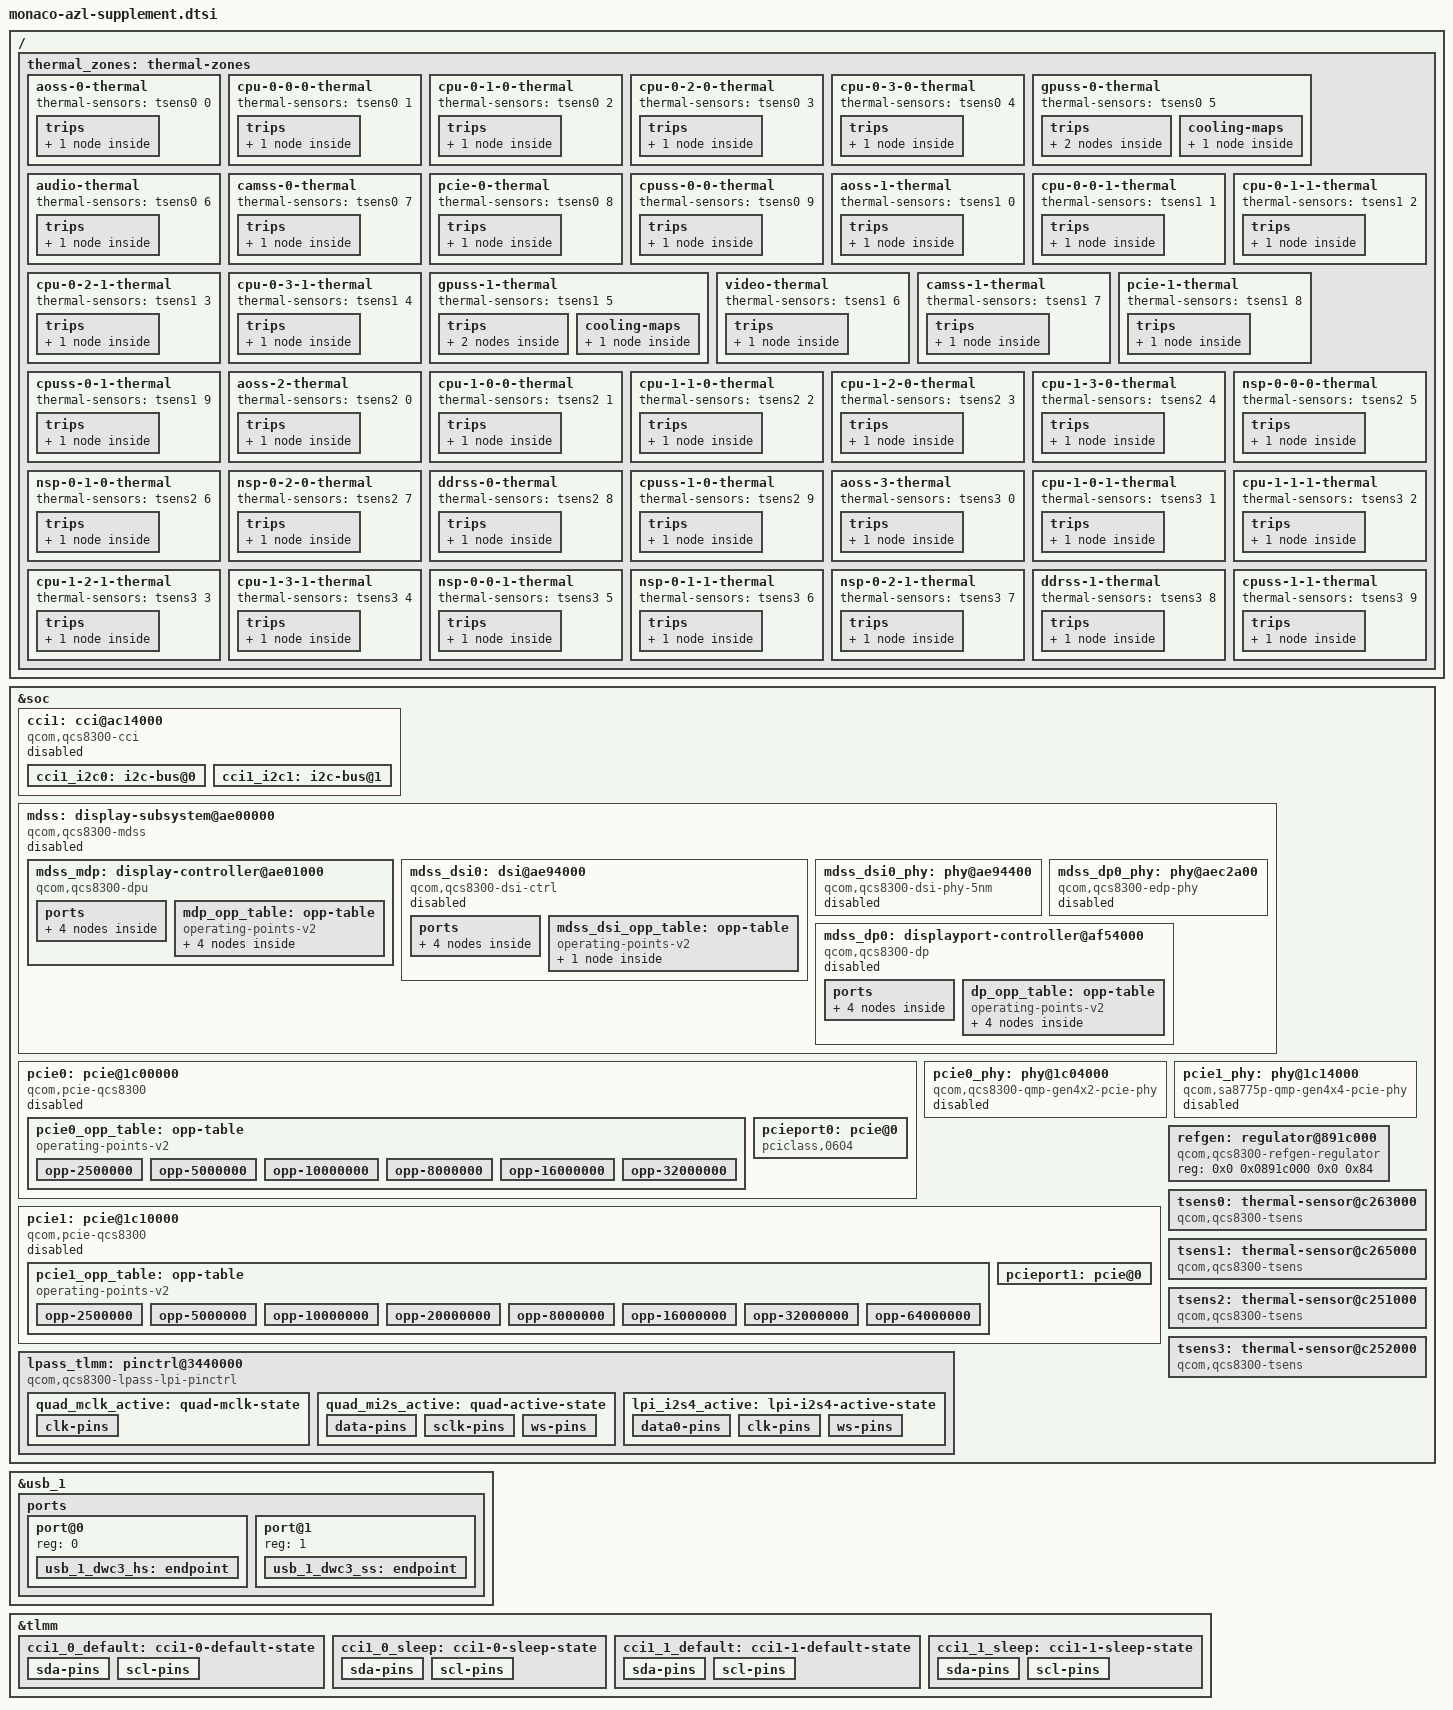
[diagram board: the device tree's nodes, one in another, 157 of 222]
// SPDX-License-Identifier: BSD-3-Clause
/*
 * Supplement for the Azure Linux 6.18 qcs8300.dtsi: the Monaco node
 * subtrees the Arduino Monza board files reference that the Azure
 * tree's SoC file does not carry. Extracted from upstream
 * monaco.dtsi (torvalds/linux) Nov 9, 2026: display (mdss with its
 * dp/dsi children), PCIe controllers and PHYs, camera CCI, refgen,
 * the thermal sensors, and the Type-C graph endpoints. The thermal
 * bindings include comes with it; upstream monaco.dtsi provides
 * THERMAL_NO_LIMIT transitively and the Azure file does not.
 */

#include <dt-bindings/clock/qcom,dsi-phy-28nm.h>
#include <dt-bindings/thermal/thermal.h>

&soc {
			cci1: cci@ac14000 {

				compatible = "qcom,qcs8300-cci", "qcom,msm8996-cci";

				reg = <0x0 0x0ac14000 0x0 0x1000>;



				interrupts = <GIC_SPI 271 IRQ_TYPE_EDGE_RISING>;



				clocks = <&camcc CAM_CC_CPAS_AHB_CLK>,

					 <&camcc CAM_CC_CCI_1_CLK>;

				clock-names = "ahb",

					      "cci";



				power-domains = <&camcc CAM_CC_TITAN_TOP_GDSC>;



				pinctrl-0 = <&cci1_0_default &cci1_1_default>;

				pinctrl-1 = <&cci1_0_sleep &cci1_1_sleep>;

				pinctrl-names = "default", "sleep";



				#address-cells = <1>;

				#size-cells = <0>;



				status = "disabled";



				cci1_i2c0: i2c-bus@0 {

					reg = <0>;

					clock-frequency = <400000>;

					#address-cells = <1>;

					#size-cells = <0>;

				};



				cci1_i2c1: i2c-bus@1 {

					reg = <1>;

					clock-frequency = <400000>;

					#address-cells = <1>;

					#size-cells = <0>;

				};

			};



			mdss: display-subsystem@ae00000 {

				compatible = "qcom,qcs8300-mdss";

				reg = <0x0 0x0ae00000 0x0 0x1000>;

				reg-names = "mdss";



				interrupts = <GIC_SPI 92 IRQ_TYPE_LEVEL_HIGH>;



				clocks = <&dispcc MDSS_DISP_CC_MDSS_AHB_CLK>,

					 <&gcc GCC_DISP_HF_AXI_CLK>,

					 <&dispcc MDSS_DISP_CC_MDSS_MDP_CLK>;



				resets = <&dispcc MDSS_DISP_CC_MDSS_CORE_BCR>;



				interconnects = <&mmss_noc MASTER_MDP0 QCOM_ICC_TAG_ALWAYS

						 &mc_virt SLAVE_EBI1 QCOM_ICC_TAG_ALWAYS>,

						<&mmss_noc MASTER_MDP1 QCOM_ICC_TAG_ALWAYS

						 &mc_virt SLAVE_EBI1 QCOM_ICC_TAG_ALWAYS>,

						<&gem_noc MASTER_APPSS_PROC QCOM_ICC_TAG_ACTIVE_ONLY

						 &config_noc SLAVE_DISPLAY_CFG QCOM_ICC_TAG_ACTIVE_ONLY>;

				interconnect-names = "mdp0-mem",

						     "mdp1-mem",

						     "cpu-cfg";



				power-domains = <&dispcc MDSS_DISP_CC_MDSS_CORE_GDSC>;



				iommus = <&apps_smmu 0x1000 0x402>;



				interrupt-controller;

				#interrupt-cells = <1>;



				#address-cells = <2>;

				#size-cells = <2>;

				ranges;



				status = "disabled";



				mdss_mdp: display-controller@ae01000 {

					compatible = "qcom,qcs8300-dpu", "qcom,sa8775p-dpu";

					reg = <0x0 0x0ae01000 0x0 0x8f000>,

					      <0x0 0x0aeb0000 0x0 0x2008>;

					reg-names = "mdp", "vbif";



					interrupts-extended = <&mdss 0>;



					clocks = <&gcc GCC_DISP_HF_AXI_CLK>,

						 <&dispcc MDSS_DISP_CC_MDSS_AHB_CLK>,

						 <&dispcc MDSS_DISP_CC_MDSS_MDP_LUT_CLK>,

						 <&dispcc MDSS_DISP_CC_MDSS_MDP_CLK>,

						 <&dispcc MDSS_DISP_CC_MDSS_VSYNC_CLK>;

					clock-names = "nrt_bus",

						      "iface",

						      "lut",

						      "core",

						      "vsync";



					assigned-clocks = <&dispcc MDSS_DISP_CC_MDSS_VSYNC_CLK>;

					assigned-clock-rates = <19200000>;



					operating-points-v2 = <&mdp_opp_table>;

					power-domains = <&rpmhpd RPMHPD_MMCX>;



					ports {

						#address-cells = <1>;

						#size-cells = <0>;



						port@0 {

							reg = <0>;



							dpu_intf0_out: endpoint {



								remote-endpoint = <&mdss_dp0_in>;

							};

						};



						port@1 {

							reg = <1>;



							dpu_intf1_out: endpoint {



								remote-endpoint = <&mdss_dsi0_in>;

							};

						};

					};



					mdp_opp_table: opp-table {

						compatible = "operating-points-v2";



						opp-375000000 {

							opp-hz = /bits/ 64 <375000000>;

							required-opps = <&rpmhpd_opp_svs_l1>;

						};



						opp-500000000 {

							opp-hz = /bits/ 64 <500000000>;

							required-opps = <&rpmhpd_opp_nom>;

						};



						opp-575000000 {

							opp-hz = /bits/ 64 <575000000>;

							required-opps = <&rpmhpd_opp_turbo>;

						};



						opp-650000000 {

							opp-hz = /bits/ 64 <650000000>;

							required-opps = <&rpmhpd_opp_turbo_l1>;

						};

					};

				};



				mdss_dsi0: dsi@ae94000 {

					compatible = "qcom,qcs8300-dsi-ctrl",

						     "qcom,sa8775p-dsi-ctrl",

						     "qcom,mdss-dsi-ctrl";

					reg = <0x0 0x0ae94000 0x0 0x400>;

					reg-names = "dsi_ctrl";



					interrupt-parent = <&mdss>;

					interrupts = <4>;



					clocks = <&dispcc MDSS_DISP_CC_MDSS_BYTE0_CLK>,

						 <&dispcc MDSS_DISP_CC_MDSS_BYTE0_INTF_CLK>,

						 <&dispcc MDSS_DISP_CC_MDSS_PCLK0_CLK>,

						 <&dispcc MDSS_DISP_CC_MDSS_ESC0_CLK>,

						 <&dispcc MDSS_DISP_CC_MDSS_AHB_CLK>,

						 <&gcc GCC_DISP_HF_AXI_CLK>;

					clock-names = "byte",

						      "byte_intf",

						      "pixel",

						      "core",

						      "iface",

						      "bus";



					assigned-clocks = <&dispcc MDSS_DISP_CC_MDSS_BYTE0_CLK_SRC>,

							  <&dispcc MDSS_DISP_CC_MDSS_PCLK0_CLK_SRC>;

					assigned-clock-parents = <&mdss_dsi0_phy DSI_BYTE_PLL_CLK>,

								 <&mdss_dsi0_phy DSI_PIXEL_PLL_CLK>;



					phys = <&mdss_dsi0_phy>;



					operating-points-v2 = <&mdss_dsi_opp_table>;

					power-domains = <&rpmhpd RPMHPD_MMCX>;



					refgen-supply = <&refgen>;



					#address-cells = <1>;

					#size-cells = <0>;



					status = "disabled";



					ports {

						#address-cells = <1>;

						#size-cells = <0>;



						port@0 {

							reg = <0>;



							mdss_dsi0_in: endpoint {



								remote-endpoint = <&dpu_intf1_out>;

							};

						};



						port@1 {

							reg = <1>;



							mdss_dsi0_out: endpoint {

							};

						};

					};



					mdss_dsi_opp_table: opp-table {

						compatible = "operating-points-v2";



						opp-358000000 {

							opp-hz = /bits/ 64 <358000000>;

							required-opps = <&rpmhpd_opp_svs_l1>;

						};

					};

				};



				mdss_dsi0_phy: phy@ae94400 {

					compatible = "qcom,qcs8300-dsi-phy-5nm",

						     "qcom,sa8775p-dsi-phy-5nm";

					reg = <0x0 0x0ae94400 0x0 0x200>,

					      <0x0 0x0ae94600 0x0 0x280>,

					      <0x0 0x0ae94900 0x0 0x280>;

					reg-names = "dsi_phy",

						    "dsi_phy_lane",

						    "dsi_pll";



					#clock-cells = <1>;

					#phy-cells = <0>;



					clocks = <&dispcc MDSS_DISP_CC_MDSS_AHB_CLK>,

						 <&rpmhcc RPMH_CXO_CLK>;

					clock-names = "iface",

						      "ref";



					status = "disabled";

				};



				mdss_dp0_phy: phy@aec2a00 {

					compatible = "qcom,qcs8300-edp-phy", "qcom,sa8775p-edp-phy";



					reg = <0x0 0x0aec2a00 0x0 0x19c>,

					      <0x0 0x0aec2200 0x0 0xec>,

					      <0x0 0x0aec2600 0x0 0xec>,

					      <0x0 0x0aec2000 0x0 0x1c8>;



					clocks = <&dispcc MDSS_DISP_CC_MDSS_DPTX0_AUX_CLK>,

						 <&dispcc MDSS_DISP_CC_MDSS_AHB_CLK>;

					clock-names = "aux",

						      "cfg_ahb";



					power-domains = <&rpmhpd RPMHPD_MX>;



					#clock-cells = <1>;

					#phy-cells = <0>;



					status = "disabled";

				};



				mdss_dp0: displayport-controller@af54000 {

					compatible = "qcom,qcs8300-dp", "qcom,sa8775p-dp";



					reg = <0x0 0x0af54000 0x0 0x200>,

					      <0x0 0x0af54200 0x0 0x200>,

					      <0x0 0x0af55000 0x0 0xc00>,

					      <0x0 0x0af56000 0x0 0x09c>,

					      <0x0 0x0af57000 0x0 0x09c>,

					      <0x0 0x0af58000 0x0 0x09c>,

					      <0x0 0x0af59000 0x0 0x09c>,

					      <0x0 0x0af5a000 0x0 0x23c>,

					      <0x0 0x0af5b000 0x0 0x23c>;



					interrupts-extended = <&mdss 12>;



					clocks = <&dispcc MDSS_DISP_CC_MDSS_AHB_CLK>,

						 <&dispcc MDSS_DISP_CC_MDSS_DPTX0_AUX_CLK>,

						 <&dispcc MDSS_DISP_CC_MDSS_DPTX0_LINK_CLK>,

						 <&dispcc MDSS_DISP_CC_MDSS_DPTX0_LINK_INTF_CLK>,

						 <&dispcc MDSS_DISP_CC_MDSS_DPTX0_PIXEL0_CLK>,

						 <&dispcc MDSS_DISP_CC_MDSS_DPTX0_PIXEL1_CLK>,

						 <&dispcc MDSS_DISP_CC_MDSS_DPTX0_PIXEL2_CLK>,

						 <&dispcc MDSS_DISP_CC_MDSS_DPTX0_PIXEL3_CLK>;

					clock-names = "core_iface",

						      "core_aux",

						      "ctrl_link",

						      "ctrl_link_iface",

						      "stream_pixel",

						      "stream_1_pixel",

						      "stream_2_pixel",

						      "stream_3_pixel";

					assigned-clocks = <&dispcc MDSS_DISP_CC_MDSS_DPTX0_LINK_CLK_SRC>,

							  <&dispcc MDSS_DISP_CC_MDSS_DPTX0_PIXEL0_CLK_SRC>,

							  <&dispcc MDSS_DISP_CC_MDSS_DPTX0_PIXEL1_CLK_SRC>,

							  <&dispcc MDSS_DISP_CC_MDSS_DPTX0_PIXEL2_CLK_SRC>,

							  <&dispcc MDSS_DISP_CC_MDSS_DPTX0_PIXEL3_CLK_SRC>;

					assigned-clock-parents = <&mdss_dp0_phy 0>,

								 <&mdss_dp0_phy 1>,

								 <&mdss_dp0_phy 1>,

								 <&mdss_dp0_phy 1>,

								 <&mdss_dp0_phy 1>;

					phys = <&mdss_dp0_phy>;

					phy-names = "dp";



					operating-points-v2 = <&dp_opp_table>;

					power-domains = <&rpmhpd RPMHPD_MMCX>;



					#sound-dai-cells = <0>;



					status = "disabled";



					ports {

						#address-cells = <1>;

						#size-cells = <0>;



						port@0 {

							reg = <0>;



							mdss_dp0_in: endpoint {

								remote-endpoint = <&dpu_intf0_out>;

							};

						};



						port@1 {

							reg = <1>;



							mdss_dp0_out: endpoint { };

						};

					};



					dp_opp_table: opp-table {

						compatible = "operating-points-v2";



						opp-162000000 {

							opp-hz = /bits/ 64 <162000000>;

							required-opps = <&rpmhpd_opp_low_svs>;

						};



						opp-270000000 {

							opp-hz = /bits/ 64 <270000000>;

							required-opps = <&rpmhpd_opp_svs>;

						};



						opp-540000000 {

							opp-hz = /bits/ 64 <540000000>;

							required-opps = <&rpmhpd_opp_svs_l1>;

						};



						opp-810000000 {

							opp-hz = /bits/ 64 <810000000>;

							required-opps = <&rpmhpd_opp_nom>;

						};

					};

				};

			};



			pcie0: pcie@1c00000 {

				device_type = "pci";

				compatible = "qcom,pcie-qcs8300", "qcom,pcie-sa8775p";

				reg = <0x0 0x01c00000 0x0 0x3000>,

				      <0x0 0x40000000 0x0 0xf20>,

				      <0x0 0x40000f20 0x0 0xa8>,

				      <0x0 0x40001000 0x0 0x4000>,

				      <0x0 0x40100000 0x0 0x100000>,

				      <0x0 0x01c03000 0x0 0x1000>;

				reg-names = "parf",

					    "dbi",

					    "elbi",

					    "atu",

					    "config",

					    "mhi";

				#address-cells = <3>;

				#size-cells = <2>;

				ranges = <0x01000000 0x0 0x00000000 0x0 0x40200000 0x0 0x100000>,

					 <0x02000000 0x0 0x40300000 0x0 0x40300000 0x0 0x1fd00000>;

				bus-range = <0x00 0xff>;



				dma-coherent;



				linux,pci-domain = <0>;

				num-lanes = <2>;



				interrupts = <GIC_SPI 307 IRQ_TYPE_LEVEL_HIGH>,

					     <GIC_SPI 308 IRQ_TYPE_LEVEL_HIGH>,

					     <GIC_SPI 309 IRQ_TYPE_LEVEL_HIGH>,

					     <GIC_SPI 312 IRQ_TYPE_LEVEL_HIGH>,

					     <GIC_SPI 313 IRQ_TYPE_LEVEL_HIGH>,

					     <GIC_SPI 314 IRQ_TYPE_LEVEL_HIGH>,

					     <GIC_SPI 374 IRQ_TYPE_LEVEL_HIGH>,

					     <GIC_SPI 375 IRQ_TYPE_LEVEL_HIGH>,

					     <GIC_SPI 306 IRQ_TYPE_LEVEL_HIGH>;

				interrupt-names = "msi0",

						  "msi1",

						  "msi2",

						  "msi3",

						  "msi4",

						  "msi5",

						  "msi6",

						  "msi7",

						  "global";



				#interrupt-cells = <1>;

				interrupt-map-mask = <0 0 0 0x7>;

				interrupt-map = <0 0 0 1 &intc GIC_SPI 434 IRQ_TYPE_LEVEL_HIGH>,

						<0 0 0 2 &intc GIC_SPI 435 IRQ_TYPE_LEVEL_HIGH>,

						<0 0 0 3 &intc GIC_SPI 438 IRQ_TYPE_LEVEL_HIGH>,

						<0 0 0 4 &intc GIC_SPI 439 IRQ_TYPE_LEVEL_HIGH>;



				clocks = <&gcc GCC_PCIE_0_AUX_CLK>,

					 <&gcc GCC_PCIE_0_CFG_AHB_CLK>,

					 <&gcc GCC_PCIE_0_MSTR_AXI_CLK>,

					 <&gcc GCC_PCIE_0_SLV_AXI_CLK>,

					 <&gcc GCC_PCIE_0_SLV_Q2A_AXI_CLK>;

				clock-names = "aux",

					      "cfg",

					      "bus_master",

					      "bus_slave",

					      "slave_q2a";



				assigned-clocks = <&gcc GCC_PCIE_0_AUX_CLK>;

				assigned-clock-rates = <19200000>;



				interconnects = <&pcie_anoc MASTER_PCIE_0 QCOM_ICC_TAG_ALWAYS

						 &mc_virt SLAVE_EBI1 QCOM_ICC_TAG_ALWAYS>,

						<&gem_noc MASTER_APPSS_PROC QCOM_ICC_TAG_ACTIVE_ONLY

						 &config_noc SLAVE_PCIE_0 QCOM_ICC_TAG_ACTIVE_ONLY>;

				interconnect-names = "pcie-mem",

						     "cpu-pcie";



				iommu-map = <0x0 &pcie_smmu 0x0000 0x0 0x1>,

					    <0x100 &pcie_smmu 0x0001 0x0 0x1>;



				resets = <&gcc GCC_PCIE_0_BCR>,

					 <&gcc GCC_PCIE_0_LINK_DOWN_BCR>;

				reset-names = "pci",

					      "link_down";



				power-domains = <&gcc GCC_PCIE_0_GDSC>;



				eq-presets-8gts = /bits/ 16 <0x5555 0x5555>;

				eq-presets-16gts = /bits/ 8 <0x55 0x55>;



				operating-points-v2 = <&pcie0_opp_table>;



				status = "disabled";



				pcie0_opp_table: opp-table {

					compatible = "operating-points-v2";



					/* GEN 1 x1 */

					opp-2500000 {

						opp-hz = /bits/ 64 <2500000>;

						required-opps = <&rpmhpd_opp_svs_l1>;

						opp-peak-kBps = <250000 1>;

					};



					/* GEN 1 x2 and GEN 2 x1 */

					opp-5000000 {

						opp-hz = /bits/ 64 <5000000>;

						required-opps = <&rpmhpd_opp_svs_l1>;

						opp-peak-kBps = <500000 1>;

					};



					/* GEN 2 x2 */

					opp-10000000 {

						opp-hz = /bits/ 64 <10000000>;

						required-opps = <&rpmhpd_opp_svs_l1>;

						opp-peak-kBps = <1000000 1>;

					};



					/* GEN 3 x1 */

					opp-8000000 {

						opp-hz = /bits/ 64 <8000000>;

						required-opps = <&rpmhpd_opp_svs_l1>;

						opp-peak-kBps = <984500 1>;

					};



					/* GEN 3 x2 and GEN 4 x1 */

					opp-16000000 {

						opp-hz = /bits/ 64 <16000000>;

						required-opps = <&rpmhpd_opp_nom>;

						opp-peak-kBps = <1969000 1>;

					};



					/* GEN 4 x2 */

					opp-32000000 {

						opp-hz = /bits/ 64 <32000000>;

						required-opps = <&rpmhpd_opp_nom>;

						opp-peak-kBps = <3938000 1>;

					};

				};



				pcieport0: pcie@0 {

					compatible = "pciclass,0604";

					device_type = "pci";

					reg = <0x0 0x0 0x0 0x0 0x0>;

					bus-range = <0x01 0xff>;



					#address-cells = <3>;

					#size-cells = <2>;

					ranges;

					phys = <&pcie0_phy>;

				};

			};



			pcie0_phy: phy@1c04000 {

				compatible = "qcom,qcs8300-qmp-gen4x2-pcie-phy";

				reg = <0x0 0x01c04000 0x0 0x2000>;



				clocks = <&gcc GCC_PCIE_0_PHY_AUX_CLK>,

					 <&gcc GCC_PCIE_0_CFG_AHB_CLK>,

					 <&gcc GCC_PCIE_CLKREF_EN>,

					 <&gcc GCC_PCIE_0_PHY_RCHNG_CLK>,

					 <&gcc GCC_PCIE_0_PIPE_CLK>,

					 <&gcc GCC_PCIE_0_PIPEDIV2_CLK>;

				clock-names = "aux",

					      "cfg_ahb",

					      "ref",

					      "rchng",

					      "pipe",

					      "pipediv2";



				resets = <&gcc GCC_PCIE_0_PHY_BCR>;

				reset-names = "phy";



				assigned-clocks = <&gcc GCC_PCIE_0_PHY_RCHNG_CLK>;

				assigned-clock-rates = <100000000>;



				#clock-cells = <0>;

				clock-output-names = "pcie_0_pipe_clk";



				#phy-cells = <0>;



				status = "disabled";

			};



			pcie1: pcie@1c10000 {

				device_type = "pci";

				compatible = "qcom,pcie-qcs8300", "qcom,pcie-sa8775p";

				reg = <0x0 0x01c10000 0x0 0x3000>,

				      <0x0 0x60000000 0x0 0xf20>,

				      <0x0 0x60000f20 0x0 0xa8>,

				      <0x0 0x60001000 0x0 0x4000>,

				      <0x0 0x60100000 0x0 0x100000>,

				      <0x0 0x01c13000 0x0 0x1000>;

				reg-names = "parf",

					    "dbi",

					    "elbi",

					    "atu",

					    "config",

					    "mhi";

				#address-cells = <3>;

				#size-cells = <2>;

				ranges = <0x01000000 0x0 0x00000000 0x0 0x60200000 0x0 0x100000>,

					 <0x02000000 0x0 0x60300000 0x0 0x60300000 0x0 0x1fd00000>;

				bus-range = <0x00 0xff>;



				dma-coherent;



				linux,pci-domain = <1>;

				num-lanes = <4>;



				interrupts = <GIC_SPI 519 IRQ_TYPE_LEVEL_HIGH>,

					     <GIC_SPI 140 IRQ_TYPE_LEVEL_HIGH>,

					     <GIC_SPI 141 IRQ_TYPE_LEVEL_HIGH>,

					     <GIC_SPI 142 IRQ_TYPE_LEVEL_HIGH>,

					     <GIC_SPI 143 IRQ_TYPE_LEVEL_HIGH>,

					     <GIC_SPI 144 IRQ_TYPE_LEVEL_HIGH>,

					     <GIC_SPI 145 IRQ_TYPE_LEVEL_HIGH>,

					     <GIC_SPI 146 IRQ_TYPE_LEVEL_HIGH>,

					     <GIC_SPI 518 IRQ_TYPE_LEVEL_HIGH>;

				interrupt-names = "msi0",

						  "msi1",

						  "msi2",

						  "msi3",

						  "msi4",

						  "msi5",

						  "msi6",

						  "msi7",

						  "global";

				#interrupt-cells = <1>;

				interrupt-map-mask = <0 0 0 0x7>;

				interrupt-map = <0 0 0 1 &intc GIC_SPI 148 IRQ_TYPE_LEVEL_HIGH>,

						<0 0 0 2 &intc GIC_SPI 149 IRQ_TYPE_LEVEL_HIGH>,

						<0 0 0 3 &intc GIC_SPI 150 IRQ_TYPE_LEVEL_HIGH>,

						<0 0 0 4 &intc GIC_SPI 151 IRQ_TYPE_LEVEL_HIGH>;



				clocks = <&gcc GCC_PCIE_1_AUX_CLK>,

					 <&gcc GCC_PCIE_1_CFG_AHB_CLK>,

					 <&gcc GCC_PCIE_1_MSTR_AXI_CLK>,

					 <&gcc GCC_PCIE_1_SLV_AXI_CLK>,

					 <&gcc GCC_PCIE_1_SLV_Q2A_AXI_CLK>;

				clock-names = "aux",

					      "cfg",

					      "bus_master",

					      "bus_slave",

					      "slave_q2a";



				assigned-clocks = <&gcc GCC_PCIE_1_AUX_CLK>;

				assigned-clock-rates = <19200000>;



				interconnects = <&pcie_anoc MASTER_PCIE_1 QCOM_ICC_TAG_ALWAYS

						 &mc_virt SLAVE_EBI1 QCOM_ICC_TAG_ALWAYS>,

						<&gem_noc MASTER_APPSS_PROC QCOM_ICC_TAG_ACTIVE_ONLY

						 &config_noc SLAVE_PCIE_1 QCOM_ICC_TAG_ACTIVE_ONLY>;

				interconnect-names = "pcie-mem", "cpu-pcie";



				iommu-map = <0x0 &pcie_smmu 0x0080 0x0 0x1>,

					    <0x100 &pcie_smmu 0x0081 0x0 0x1>;



				resets = <&gcc GCC_PCIE_1_BCR>,

					 <&gcc GCC_PCIE_1_LINK_DOWN_BCR>;

				reset-names = "pci",

					      "link_down";



				power-domains = <&gcc GCC_PCIE_1_GDSC>;



				eq-presets-8gts = /bits/ 16 <0x5555 0x5555 0x5555 0x5555>;

				eq-presets-16gts = /bits/ 8 <0x55 0x55 0x55 0x55>;



				operating-points-v2 = <&pcie1_opp_table>;



				status = "disabled";



				pcie1_opp_table: opp-table {

					compatible = "operating-points-v2";



					/* GEN 1 x1 */

					opp-2500000 {

						opp-hz = /bits/ 64 <2500000>;

						required-opps = <&rpmhpd_opp_svs_l1>;

						opp-peak-kBps = <250000 1>;

					};



					/* GEN 1 x2 and GEN 2 x1 */

					opp-5000000 {

						opp-hz = /bits/ 64 <5000000>;

						required-opps = <&rpmhpd_opp_svs_l1>;

						opp-peak-kBps = <500000 1>;

					};



					/* GEN 1 x4 and GEN 2 x2 */

					opp-10000000 {

						opp-hz = /bits/ 64 <10000000>;

						required-opps = <&rpmhpd_opp_svs_l1>;

						opp-peak-kBps = <1000000 1>;

					};



					/* GEN 2 x4 */

					opp-20000000 {

						opp-hz = /bits/ 64 <20000000>;

						required-opps = <&rpmhpd_opp_low_svs>;

						opp-peak-kBps = <2000000 1>;

					};



					/* GEN 3 x1 */

					opp-8000000 {

						opp-hz = /bits/ 64 <8000000>;

						required-opps = <&rpmhpd_opp_svs_l1>;

						opp-peak-kBps = <984500 1>;

					};



					/* GEN 3 x2 and GEN 4 x1 */

					opp-16000000 {

						opp-hz = /bits/ 64 <16000000>;

						required-opps = <&rpmhpd_opp_nom>;

						opp-peak-kBps = <1969000 1>;

					};



					/* GEN 3 x4 and GEN 4 x2 */

					opp-32000000 {

						opp-hz = /bits/ 64 <32000000>;

						required-opps = <&rpmhpd_opp_nom>;

						opp-peak-kBps = <3938000 1>;

					};



					/* GEN 4 x4 */

					opp-64000000 {

						opp-hz = /bits/ 64 <64000000>;

						required-opps = <&rpmhpd_opp_nom>;

						opp-peak-kBps = <7876000 1>;

					};

				};



				pcieport1: pcie@0 {

					device_type = "pci";

					reg = <0x0 0x0 0x0 0x0 0x0>;

					bus-range = <0x01 0xff>;



					#address-cells = <3>;

					#size-cells = <2>;

					ranges;

					phys = <&pcie1_phy>;

				};

			};



			pcie1_phy: phy@1c14000 {

				compatible = "qcom,sa8775p-qmp-gen4x4-pcie-phy";

				reg = <0x0 0x01c14000 0x0 0x4000>;



				clocks = <&gcc GCC_PCIE_1_PHY_AUX_CLK>,

					 <&gcc GCC_PCIE_1_CFG_AHB_CLK>,

					 <&gcc GCC_PCIE_CLKREF_EN>,

					 <&gcc GCC_PCIE_1_PHY_RCHNG_CLK>,

					 <&gcc GCC_PCIE_1_PIPE_CLK>,

					 <&gcc GCC_PCIE_1_PIPEDIV2_CLK>;

				clock-names = "aux",

					      "cfg_ahb",

					      "ref",

					      "rchng",

					      "pipe",

					      "pipediv2";



				assigned-clocks = <&gcc GCC_PCIE_1_PHY_RCHNG_CLK>;

				assigned-clock-rates = <100000000>;



				resets = <&gcc GCC_PCIE_1_PHY_BCR>;

				reset-names = "phy";



				#clock-cells = <0>;

				clock-output-names = "pcie_1_pipe_clk";



				#phy-cells = <0>;



				status = "disabled";

			};



			refgen: regulator@891c000 {

				compatible = "qcom,qcs8300-refgen-regulator",

					     "qcom,sm8250-refgen-regulator";

				reg = <0x0 0x0891c000 0x0 0x84>;

			};



			tsens0: thermal-sensor@c263000 {

				compatible = "qcom,qcs8300-tsens", "qcom,tsens-v2";

				reg = <0x0 0x0c263000 0x0 0x1000>,

				      <0x0 0x0c222000 0x0 0x1000>;

				interrupts = <GIC_SPI 506 IRQ_TYPE_LEVEL_HIGH>,

					     <GIC_SPI 508 IRQ_TYPE_LEVEL_HIGH>;

				interrupt-names = "uplow", "critical";

				#qcom,sensors = <10>;

				#thermal-sensor-cells = <1>;

			};



			tsens1: thermal-sensor@c265000 {

				compatible = "qcom,qcs8300-tsens", "qcom,tsens-v2";

				reg = <0x0 0x0c265000 0x0 0x1000>,

				      <0x0 0x0c223000 0x0 0x1000>;

				interrupts = <GIC_SPI 507 IRQ_TYPE_LEVEL_HIGH>,

					     <GIC_SPI 509 IRQ_TYPE_LEVEL_HIGH>;

				interrupt-names = "uplow", "critical";

				#qcom,sensors = <10>;

				#thermal-sensor-cells = <1>;

			};



			tsens2: thermal-sensor@c251000 {

				compatible = "qcom,qcs8300-tsens", "qcom,tsens-v2";

				reg = <0x0 0x0c251000 0x0 0x1000>,

				      <0x0 0x0c224000 0x0 0x1000>;

				interrupts = <GIC_SPI 572 IRQ_TYPE_LEVEL_HIGH>,

					     <GIC_SPI 609 IRQ_TYPE_LEVEL_HIGH>;

				interrupt-names = "uplow", "critical";

				#qcom,sensors = <10>;

				#thermal-sensor-cells = <1>;

			};



			tsens3: thermal-sensor@c252000 {

				compatible = "qcom,qcs8300-tsens", "qcom,tsens-v2";

				reg = <0x0 0x0c252000 0x0 0x1000>,

				      <0x0 0x0c225000 0x0 0x1000>;

				interrupts = <GIC_SPI 573 IRQ_TYPE_LEVEL_HIGH>,

					     <GIC_SPI 610 IRQ_TYPE_LEVEL_HIGH>;

				interrupt-names = "uplow", "critical";

				#qcom,sensors = <10>;

				#thermal-sensor-cells = <1>;

			};

			lpass_tlmm: pinctrl@3440000 {
				compatible = "qcom,qcs8300-lpass-lpi-pinctrl", "qcom,sm8450-lpass-lpi-pinctrl";
				reg = <0x0 0x03440000 0x0 0x20000>,
				      <0x0 0x034d0000 0x0 0x10000>;

				clocks = <&q6prmcc LPASS_HW_MACRO_VOTE LPASS_CLK_ATTRIBUTE_COUPLE_NO>,
					 <&q6prmcc LPASS_HW_DCODEC_VOTE LPASS_CLK_ATTRIBUTE_COUPLE_NO>;
				clock-names = "core", "audio";

				gpio-controller;
				#gpio-cells = <2>;
				gpio-ranges = <&lpass_tlmm 0 0 23>;

				quad_mclk_active: quad-mclk-state {
					clk-pins {
						pins = "gpio5";
						function = "ext_mclk1_c";
						drive-strength = <8>;
						bias-disable;
					};
				};

				quad_mi2s_active: quad-active-state {
					data-pins {
						pins = "gpio2", "gpio3";
						function = "qua_mi2s_data";
						drive-strength = <8>;
						bias-disable;
					};

					sclk-pins {
						pins = "gpio0";
						function = "qua_mi2s_sclk";
						drive-strength = <8>;
						bias-disable;
					};

					ws-pins {
						pins = "gpio1";
						function = "qua_mi2s_ws";
						drive-strength = <8>;
						bias-disable;
					};
				};

				lpi_i2s4_active: lpi-i2s4-active-state {
					data0-pins {
						pins = "gpio17";
						function = "i2s4_data";
						drive-strength = <8>;
						bias-disable;
					};

					clk-pins {
						pins = "gpio12";
						function = "i2s4_clk";
						drive-strength = <8>;
						bias-disable;
					};

					ws-pins {
						pins = "gpio13";
						function = "i2s4_ws";
						drive-strength = <8>;
						bias-disable;
					};
				};
			};
};

&usb_1 {
	ports {
		#address-cells = <1>;
		#size-cells = <0>;

		port@0 {
			reg = <0>;

			usb_1_dwc3_hs: endpoint {
			};
		};

		port@1 {
			reg = <1>;

			usb_1_dwc3_ss: endpoint {
			};
		};
	};
};

&tlmm {
				cci1_0_default: cci1-0-default-state {

					sda-pins {

						pins = "gpio59";

						function = "cci_i2c_sda";

						drive-strength = <2>;

						bias-pull-up = <2200>;

					};



					scl-pins {

						pins = "gpio60";

						function = "cci_i2c_scl";

						drive-strength = <2>;

						bias-pull-up = <2200>;

					};

				};



				cci1_0_sleep: cci1-0-sleep-state {

					sda-pins {

						pins = "gpio59";

						function = "cci_i2c_sda";

						drive-strength = <2>;

						bias-pull-down;

					};



					scl-pins {

						pins = "gpio60";

						function = "cci_i2c_scl";

						drive-strength = <2>;

						bias-pull-down;

					};

				};



				cci1_1_default: cci1-1-default-state {

					sda-pins {

						pins = "gpio31";

						function = "cci_i2c_sda";

						drive-strength = <2>;

						bias-pull-up = <2200>;

					};



					scl-pins {

						pins = "gpio32";

						function = "cci_i2c_scl";

						drive-strength = <2>;

						bias-pull-up = <2200>;

					};

				};



				cci1_1_sleep: cci1-1-sleep-state {

					sda-pins {

						pins = "gpio31";

						function = "cci_i2c_sda";

						drive-strength = <2>;

						bias-pull-down;

					};



					scl-pins {

						pins = "gpio32";

						function = "cci_i2c_scl";

						drive-strength = <2>;

						bias-pull-down;

					};

				};
};

/ {
	thermal_zones: thermal-zones {
		aoss-0-thermal {
			thermal-sensors = <&tsens0 0>;

			trips {
				aoss0-critical {
					temperature = <125000>;
					hysteresis = <1000>;
					type = "critical";
				};
			};
		};

		cpu-0-0-0-thermal {
			thermal-sensors = <&tsens0 1>;

			trips {
				cpu-critical {
					temperature = <125000>;
					hysteresis = <1000>;
					type = "critical";
				};
			};
		};

		cpu-0-1-0-thermal {
			thermal-sensors = <&tsens0 2>;

			trips {
				cpu-critical {
					temperature = <125000>;
					hysteresis = <1000>;
					type = "critical";
				};
			};
		};

		cpu-0-2-0-thermal {
			thermal-sensors = <&tsens0 3>;

			trips {
				cpu-critical {
					temperature = <125000>;
					hysteresis = <1000>;
					type = "critical";
				};
			};
		};

		cpu-0-3-0-thermal {
			thermal-sensors = <&tsens0 4>;

			trips {
				cpu-critical {
					temperature = <125000>;
					hysteresis = <1000>;
					type = "critical";
				};
			};
		};

		gpuss-0-thermal {
			thermal-sensors = <&tsens0 5>;

			trips {
				gpuss0_alert0: trip-point0 {
					temperature = <115000>;
					hysteresis = <5000>;
					type = "passive";
				};

				gpuss0-critical {
					temperature = <125000>;
					hysteresis = <1000>;
					type = "critical";
				};
			};

			cooling-maps {
				map0 {
					trip = <&gpuss0_alert0>;
					cooling-device = <&gpu THERMAL_NO_LIMIT THERMAL_NO_LIMIT>;
				};
			};
		};

		audio-thermal {
			thermal-sensors = <&tsens0 6>;

			trips {
				audio-critical {
					temperature = <125000>;
					hysteresis = <1000>;
					type = "critical";
				};
			};
		};

		camss-0-thermal {
			thermal-sensors = <&tsens0 7>;

			trips {
				camss-critical {
					temperature = <125000>;
					hysteresis = <1000>;
					type = "critical";
				};
			};
		};

		pcie-0-thermal {
			thermal-sensors = <&tsens0 8>;

			trips {
				pcie-critical {
					temperature = <125000>;
					hysteresis = <1000>;
					type = "critical";
				};
			};
		};

		cpuss-0-0-thermal {
			thermal-sensors = <&tsens0 9>;

			trips {
				cpuss0-critical {
					temperature = <125000>;
					hysteresis = <1000>;
					type = "critical";
				};
			};
		};

		aoss-1-thermal {
			thermal-sensors = <&tsens1 0>;

			trips {
				aoss1-critical {
					temperature = <125000>;
					hysteresis = <1000>;
					type = "critical";
				};
			};
		};

		cpu-0-0-1-thermal {
			thermal-sensors = <&tsens1 1>;

			trips {
				cpu-critical {
					temperature = <125000>;
					hysteresis = <1000>;
					type = "critical";
				};
			};
		};

		cpu-0-1-1-thermal {
			thermal-sensors = <&tsens1 2>;

			trips {
				cpu-critical {
					temperature = <125000>;
					hysteresis = <1000>;
					type = "critical";
				};
			};
		};

		cpu-0-2-1-thermal {
			thermal-sensors = <&tsens1 3>;

			trips {
				cpu-critical {
					temperature = <125000>;
					hysteresis = <1000>;
					type = "critical";
				};
			};
		};

		cpu-0-3-1-thermal {
			thermal-sensors = <&tsens1 4>;

			trips {
				cpu-critical {
					temperature = <125000>;
					hysteresis = <1000>;
					type = "critical";
				};
			};
		};

		gpuss-1-thermal {
			thermal-sensors = <&tsens1 5>;

			trips {
				gpuss1_alert0: trip-point0 {
					temperature = <115000>;
					hysteresis = <5000>;
					type = "passive";
				};

				gpuss1-critical {
					temperature = <125000>;
					hysteresis = <1000>;
					type = "critical";
				};
			};

			cooling-maps {
				map0 {
					trip = <&gpuss1_alert0>;
					cooling-device = <&gpu THERMAL_NO_LIMIT THERMAL_NO_LIMIT>;
				};
			};
		};

		video-thermal {
			thermal-sensors = <&tsens1 6>;

			trips {
				video-critical {
					temperature = <125000>;
					hysteresis = <1000>;
					type = "critical";
				};
			};
		};

		camss-1-thermal {
			thermal-sensors = <&tsens1 7>;

			trips {
				camss1-critical {
					temperature = <125000>;
					hysteresis = <1000>;
					type = "critical";
				};
			};
		};

		pcie-1-thermal {
			thermal-sensors = <&tsens1 8>;

			trips {
				pcie-critical {
					temperature = <125000>;
					hysteresis = <1000>;
					type = "critical";
				};
			};
		};

		cpuss-0-1-thermal {
			thermal-sensors = <&tsens1 9>;

			trips {
				cpuss0-critical {
					temperature = <125000>;
					hysteresis = <1000>;
					type = "critical";
				};
			};
		};

		aoss-2-thermal {
			thermal-sensors = <&tsens2 0>;

			trips {
				aoss2-critical {
					temperature = <125000>;
					hysteresis = <1000>;
					type = "critical";
				};
			};
		};

		cpu-1-0-0-thermal {
			thermal-sensors = <&tsens2 1>;

			trips {
				cpu-critical {
					temperature = <125000>;
					hysteresis = <1000>;
					type = "critical";
				};
			};
		};

		cpu-1-1-0-thermal {
			thermal-sensors = <&tsens2 2>;

			trips {
				cpu-critical {
					temperature = <125000>;
					hysteresis = <1000>;
					type = "critical";
				};
			};
		};

		cpu-1-2-0-thermal {
			thermal-sensors = <&tsens2 3>;

			trips {
				cpu-critical {
					temperature = <125000>;
					hysteresis = <1000>;
					type = "critical";
				};
			};
		};

		cpu-1-3-0-thermal {
			thermal-sensors = <&tsens2 4>;

			trips {
				cpu-critical {
					temperature = <125000>;
					hysteresis = <1000>;
					type = "critical";
				};
			};
		};

		nsp-0-0-0-thermal {
			thermal-sensors = <&tsens2 5>;

			trips {
				nsp-critical {
					temperature = <125000>;
					hysteresis = <1000>;
					type = "critical";
				};
			};
		};

		nsp-0-1-0-thermal {
			thermal-sensors = <&tsens2 6>;

			trips {
				nsp-critical {
					temperature = <125000>;
					hysteresis = <1000>;
					type = "critical";
				};
			};
		};

		nsp-0-2-0-thermal {
			thermal-sensors = <&tsens2 7>;

			trips {
				nsp-critical {
					temperature = <125000>;
					hysteresis = <1000>;
					type = "critical";
				};
			};
		};

		ddrss-0-thermal {
			thermal-sensors = <&tsens2 8>;

			trips {
				ddrss-critical {
					temperature = <125000>;
					hysteresis = <1000>;
					type = "critical";
				};
			};
		};

		cpuss-1-0-thermal {
			thermal-sensors = <&tsens2 9>;

			trips {
				cpuss1-critical {
					temperature = <125000>;
					hysteresis = <1000>;
					type = "critical";
				};
			};
		};

		aoss-3-thermal {
			thermal-sensors = <&tsens3 0>;

			trips {
				aoss3-critical {
					temperature = <125000>;
					hysteresis = <1000>;
					type = "critical";
				};
			};
		};

		cpu-1-0-1-thermal {
			thermal-sensors = <&tsens3 1>;

			trips {
				cpu-critical {
					temperature = <125000>;
					hysteresis = <1000>;
					type = "critical";
				};
			};
		};

		cpu-1-1-1-thermal {
			thermal-sensors = <&tsens3 2>;

			trips {
				cpu-critical {
					temperature = <125000>;
					hysteresis = <1000>;
					type = "critical";
				};
			};
		};

		cpu-1-2-1-thermal {
			thermal-sensors = <&tsens3 3>;

			trips {
				cpu-critical {
					temperature = <125000>;
					hysteresis = <1000>;
					type = "critical";
				};
			};
		};

		cpu-1-3-1-thermal {
			thermal-sensors = <&tsens3 4>;

			trips {
				cpu-critical {
					temperature = <125000>;
					hysteresis = <1000>;
					type = "critical";
				};
			};
		};

		nsp-0-0-1-thermal {
			thermal-sensors = <&tsens3 5>;

			trips {
				nsp-critical {
					temperature = <125000>;
					hysteresis = <1000>;
					type = "critical";
				};
			};
		};

		nsp-0-1-1-thermal {
			thermal-sensors = <&tsens3 6>;

			trips {
				nsp-critical {
					temperature = <125000>;
					hysteresis = <1000>;
					type = "critical";
				};
			};
		};

		nsp-0-2-1-thermal {
			thermal-sensors = <&tsens3 7>;

			trips {
				nsp-critical {
					temperature = <125000>;
					hysteresis = <1000>;
					type = "critical";
				};
			};
		};

		ddrss-1-thermal {
			thermal-sensors = <&tsens3 8>;

			trips {
				ddrss-critical {
					temperature = <125000>;
					hysteresis = <1000>;
					type = "critical";
				};
			};
		};

		cpuss-1-1-thermal {
			thermal-sensors = <&tsens3 9>;

			trips {
				cpuss1-critical {
					temperature = <125000>;
					hysteresis = <1000>;
					type = "critical";
				};
			};
		};
	};
};
